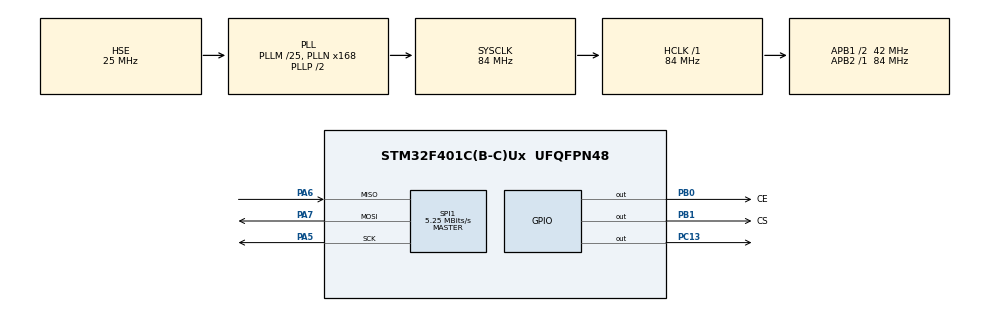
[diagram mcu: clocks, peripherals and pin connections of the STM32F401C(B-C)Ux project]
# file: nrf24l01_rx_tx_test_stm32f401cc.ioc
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Mcu.Family=STM32F4
Mcu.Name=STM32F401C(B-C)Ux
Mcu.Package=UFQFPN48
NVIC.PriorityGroup=NVIC_PRIORITYGROUP_4
PA13.Mode=Serial_Wire
PA13.Signal=SYS_JTMS-SWDIO
PA14.Mode=Serial_Wire
PA14.Signal=SYS_JTCK-SWCLK
PA5.Mode=Full_Duplex_Master
PA5.Signal=SPI1_SCK
PA6.Mode=Full_Duplex_Master
PA6.Signal=SPI1_MISO
PA7.Mode=Full_Duplex_Master
PA7.Signal=SPI1_MOSI
PB0.GPIO_Label=CE
PB0.Signal=GPIO_Output
PB1.GPIO_Label=CS
PB1.Signal=GPIO_Output
PC13-ANTI_TAMP.Signal=GPIO_Output
PH0\ -\ OSC_IN.Mode=HSE-External-Oscillator
PH0\ -\ OSC_IN.Signal=RCC_OSC_IN
PH1\ -\ OSC_OUT.Mode=HSE-External-Oscillator
PH1\ -\ OSC_OUT.Signal=RCC_OSC_OUT
ProjectManager.HeapSize=0x200
ProjectManager.StackSize=0x400
ProjectManager.TargetToolchain=STM32CubeIDE
RCC.48MHZClocksFreq_Value=42000000
RCC.AHBFreq_Value=84000000
RCC.APB1CLKDivider=RCC_HCLK_DIV2
RCC.APB1Freq_Value=42000000
RCC.APB1TimFreq_Value=84000000
RCC.APB2Freq_Value=84000000
RCC.APB2TimFreq_Value=84000000
RCC.CortexFreq_Value=84000000
RCC.HCLKFreq_Value=84000000
RCC.HSE_VALUE=25000000
RCC.HSI_VALUE=16000000
RCC.LSE_VALUE=32768
RCC.PLLM=25
RCC.PLLN=168
RCC.PLLSourceVirtual=RCC_PLLSOURCE_HSE
RCC.SYSCLKFreq_VALUE=84000000
RCC.SYSCLKSource=RCC_SYSCLKSOURCE_PLLCLK
RCC.VCOOutputFreq_Value=168000000
SPI1.BaudRatePrescaler=SPI_BAUDRATEPRESCALER_16
SPI1.CalculateBaudRate=5.25 MBits/s
SPI1.Direction=SPI_DIRECTION_2LINES
SPI1.Mode=SPI_MODE_MASTER
SPI1.VirtualType=VM_MASTER
board=custom

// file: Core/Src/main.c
/* USER CODE BEGIN Header */
/**
  ******************************************************************************
  * @file           : main.c
  * @brief          : Main program body
  ******************************************************************************
  * @attention
  *
  * Copyright (c) 2024 STMicroelectronics.
  * All rights reserved.
  *
  * This software is licensed under terms that can be found in the LICENSE file
  * in the root directory of this software component.
  * If no LICENSE file comes with this software, it is provided AS-IS.
  *
  ******************************************************************************
  */
/* USER CODE END Header */
#include "main.h"

/* USER CODE BEGIN Includes */
#include "NRF24L01.h"
/* USER CODE END Includes */

SPI_HandleTypeDef hspi1;

void SystemClock_Config(void);
static void MX_GPIO_Init(void);
static void MX_SPI1_Init(void);

/* USER CODE BEGIN 0 */

uint8_t TxAddress[] = {0xEE, 0xDD, 0xCC, 0xBB, 0xAA};
uint8_t TxData[] = "Hello World\n";

uint8_t RxAddress[] = {0xEE, 0xDD, 0xCC, 0xBB, 0xAA};
uint8_t RxData[32];

/* USER CODE END 0 */

int main(void)
{

  /* MCU Configuration--------------------------------------------------------*/

  /* Reset of all peripherals, Initializes the Flash interface and the Systick. */
  HAL_Init();

  /* Configure the system clock */
  SystemClock_Config();

  /* Initialize all configured peripherals */
  MX_GPIO_Init();
  MX_SPI1_Init();
  /* USER CODE BEGIN 2 */

  NRF24_Init();

  //NRF24_TxMode(TxAddress, 10);

  NRF24_RxMode(RxAddress, 10);

  /* USER CODE END 2 */

  /* Infinite loop */
  /* USER CODE BEGIN WHILE */
  while (1)
  {

//	  if(NRF24_Transmit(TxData) == 1){
//		  HAL_GPIO_TogglePin(GPIOC, GPIO_PIN_13);
//	  }
//	  HAL_Delay(100);

	  if(isDataAvailable(1) == 1){

		  NRF24_Receive(RxData);
		  HAL_GPIO_TogglePin(GPIOC, GPIO_PIN_13);
	  }

    /* USER CODE END WHILE */

  }
}

void SystemClock_Config(void)
{
  RCC_OscInitTypeDef RCC_OscInitStruct = {0};
  RCC_ClkInitTypeDef RCC_ClkInitStruct = {0};

  /** Configure the main internal regulator output voltage
  */
  __HAL_RCC_PWR_CLK_ENABLE();
  __HAL_PWR_VOLTAGESCALING_CONFIG(PWR_REGULATOR_VOLTAGE_SCALE2);

  /** Initializes the RCC Oscillators according to the specified parameters
  * in the RCC_OscInitTypeDef structure.
  */
  RCC_OscInitStruct.OscillatorType = RCC_OSCILLATORTYPE_HSE;
  RCC_OscInitStruct.HSEState = RCC_HSE_ON;
  RCC_OscInitStruct.PLL.PLLState = RCC_PLL_ON;
  RCC_OscInitStruct.PLL.PLLSource = RCC_PLLSOURCE_HSE;
  RCC_OscInitStruct.PLL.PLLM = 25;
  RCC_OscInitStruct.PLL.PLLN = 168;
  RCC_OscInitStruct.PLL.PLLP = RCC_PLLP_DIV2;
  RCC_OscInitStruct.PLL.PLLQ = 4;
  if (HAL_RCC_OscConfig(&RCC_OscInitStruct) != HAL_OK)
  {
    Error_Handler();
  }

  /** Initializes the CPU, AHB and APB buses clocks
  */
  RCC_ClkInitStruct.ClockType = RCC_CLOCKTYPE_HCLK|RCC_CLOCKTYPE_SYSCLK
                              |RCC_CLOCKTYPE_PCLK1|RCC_CLOCKTYPE_PCLK2;
  RCC_ClkInitStruct.SYSCLKSource = RCC_SYSCLKSOURCE_PLLCLK;
  RCC_ClkInitStruct.AHBCLKDivider = RCC_SYSCLK_DIV1;
  RCC_ClkInitStruct.APB1CLKDivider = RCC_HCLK_DIV2;
  RCC_ClkInitStruct.APB2CLKDivider = RCC_HCLK_DIV1;

  if (HAL_RCC_ClockConfig(&RCC_ClkInitStruct, FLASH_LATENCY_2) != HAL_OK)
  {
    Error_Handler();
  }
}

static void MX_SPI1_Init(void)
{

  /* SPI1 parameter configuration*/
  hspi1.Instance = SPI1;
  hspi1.Init.Mode = SPI_MODE_MASTER;
  hspi1.Init.Direction = SPI_DIRECTION_2LINES;
  hspi1.Init.DataSize = SPI_DATASIZE_8BIT;
  hspi1.Init.CLKPolarity = SPI_POLARITY_LOW;
  hspi1.Init.CLKPhase = SPI_PHASE_1EDGE;
  hspi1.Init.NSS = SPI_NSS_SOFT;
  hspi1.Init.BaudRatePrescaler = SPI_BAUDRATEPRESCALER_16;
  hspi1.Init.FirstBit = SPI_FIRSTBIT_MSB;
  hspi1.Init.TIMode = SPI_TIMODE_DISABLE;
  hspi1.Init.CRCCalculation = SPI_CRCCALCULATION_DISABLE;
  hspi1.Init.CRCPolynomial = 10;
  if (HAL_SPI_Init(&hspi1) != HAL_OK)
  {
    Error_Handler();
  }

}

static void MX_GPIO_Init(void)
{
  GPIO_InitTypeDef GPIO_InitStruct = {0};

  /* GPIO Ports Clock Enable */
  __HAL_RCC_GPIOC_CLK_ENABLE();
  __HAL_RCC_GPIOH_CLK_ENABLE();
  __HAL_RCC_GPIOA_CLK_ENABLE();
  __HAL_RCC_GPIOB_CLK_ENABLE();

  /*Configure GPIO pin Output Level */
  HAL_GPIO_WritePin(GPIOC, GPIO_PIN_13, GPIO_PIN_RESET);

  /*Configure GPIO pin Output Level */
  HAL_GPIO_WritePin(GPIOB, CE_Pin|CS_Pin, GPIO_PIN_RESET);

  /*Configure GPIO pin : PC13 */
  GPIO_InitStruct.Pin = GPIO_PIN_13;
  GPIO_InitStruct.Mode = GPIO_MODE_OUTPUT_PP;
  GPIO_InitStruct.Pull = GPIO_NOPULL;
  GPIO_InitStruct.Speed = GPIO_SPEED_FREQ_LOW;
  HAL_GPIO_Init(GPIOC, &GPIO_InitStruct);

  /*Configure GPIO pins : CE_Pin CS_Pin */
  GPIO_InitStruct.Pin = CE_Pin|CS_Pin;
  GPIO_InitStruct.Mode = GPIO_MODE_OUTPUT_PP;
  GPIO_InitStruct.Pull = GPIO_NOPULL;
  GPIO_InitStruct.Speed = GPIO_SPEED_FREQ_LOW;
  HAL_GPIO_Init(GPIOB, &GPIO_InitStruct);

}

void Error_Handler(void)
{
  __disable_irq();
  while (1)
  {
  }
}
